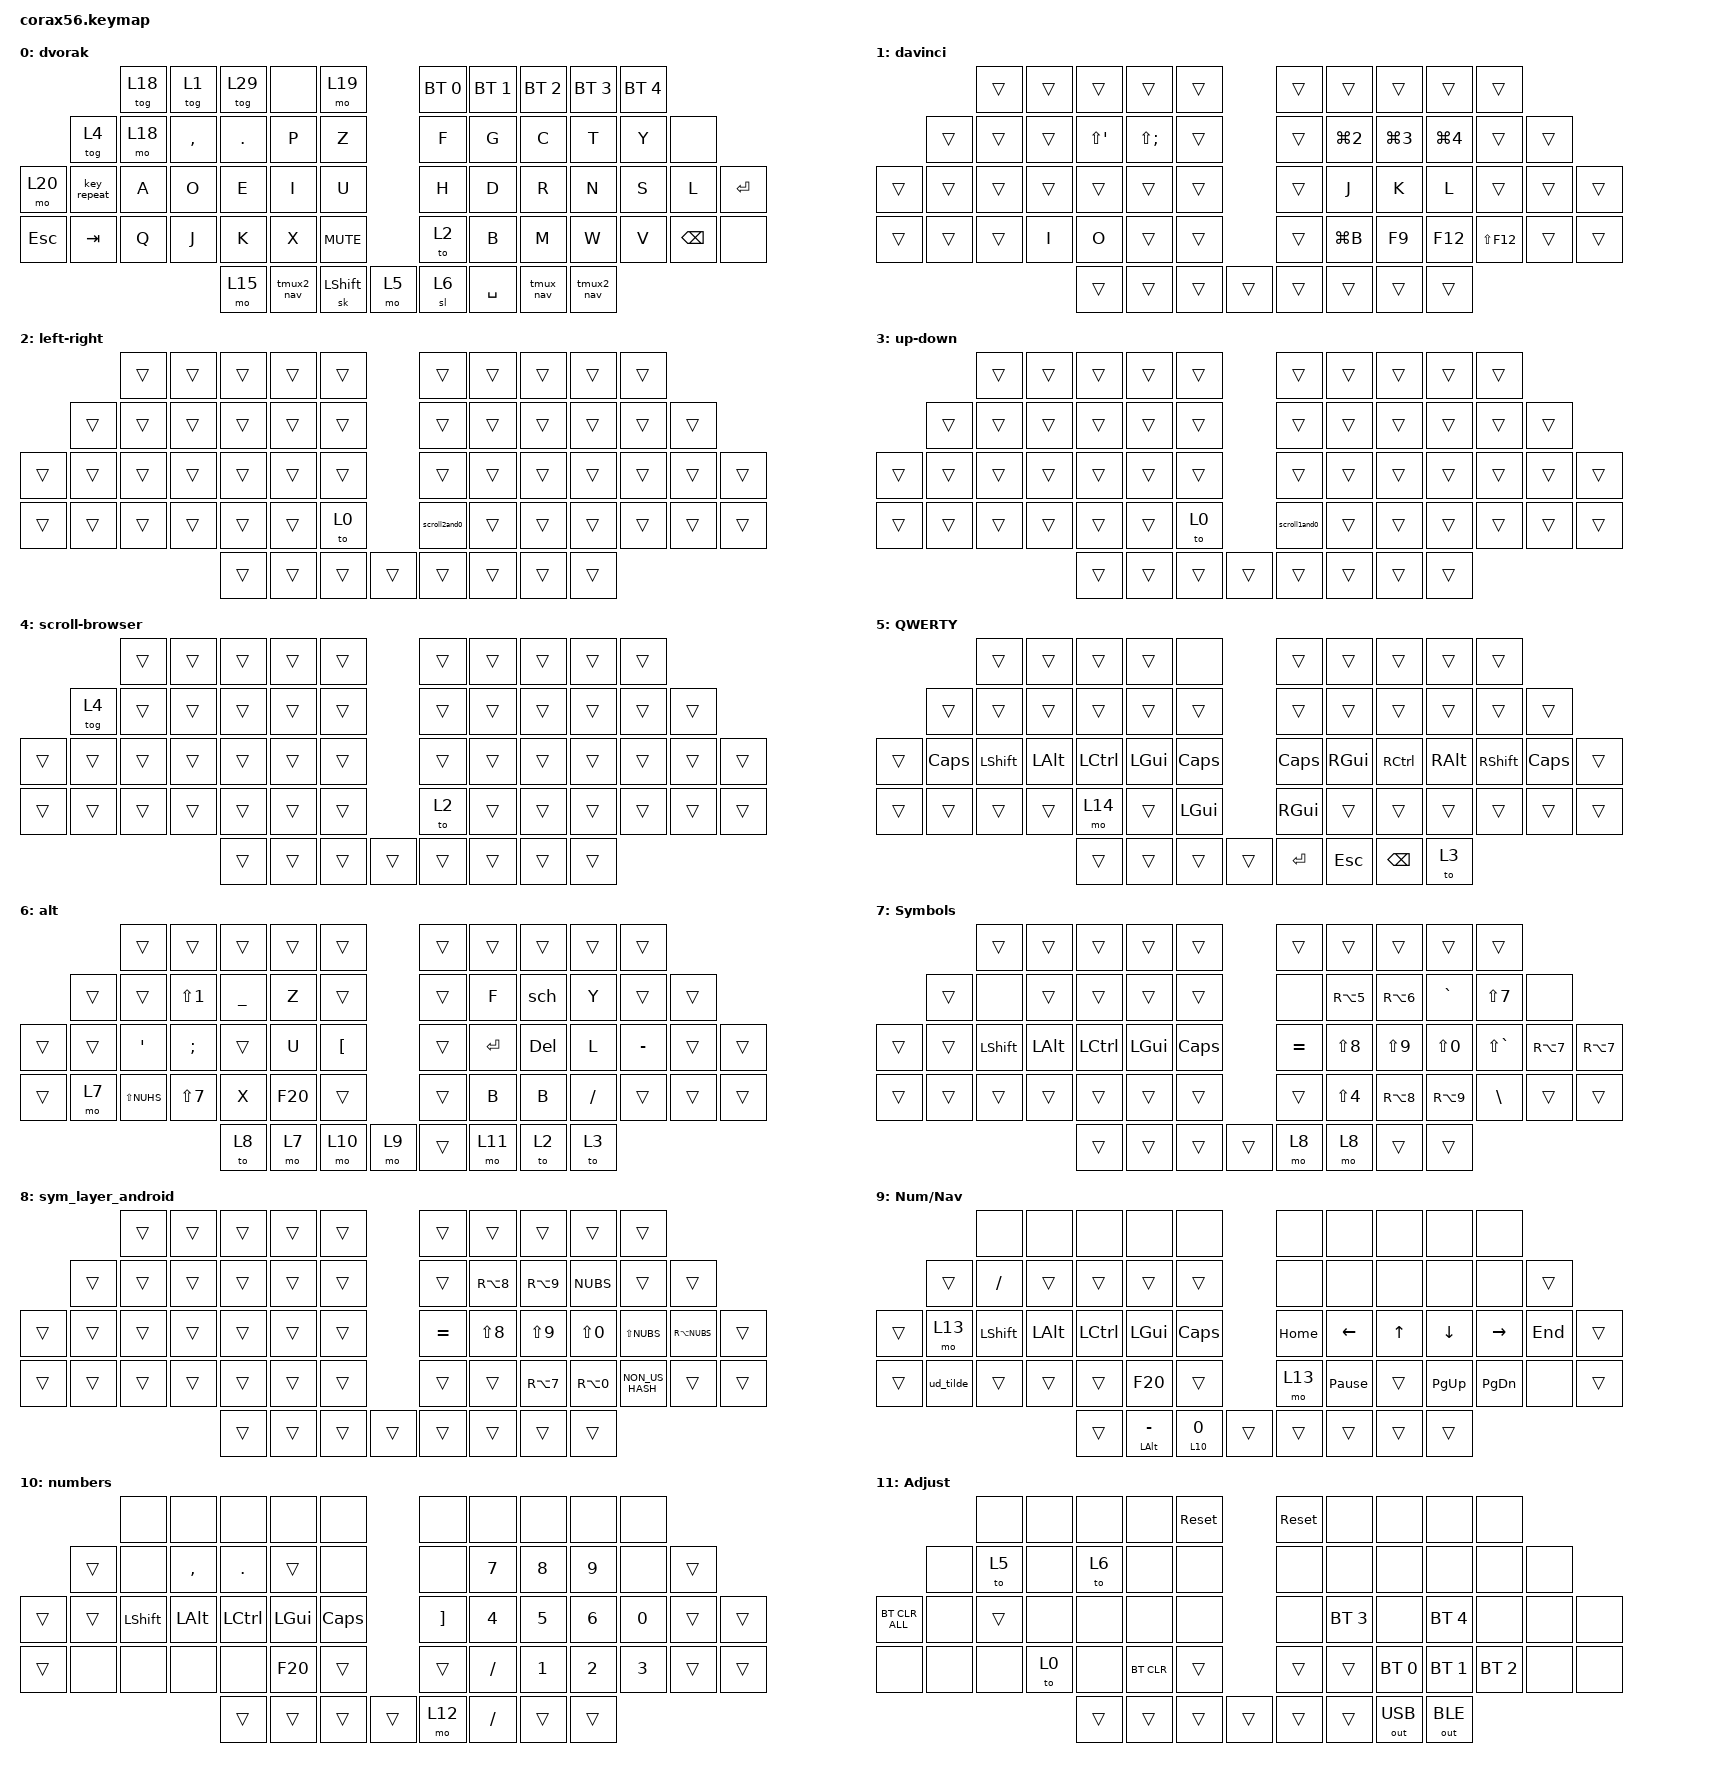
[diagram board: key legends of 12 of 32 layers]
#include <behaviors.dtsi>
#include <dt-bindings/zmk/bt.h>
#include <dt-bindings/zmk/keys.h>
#include <dt-bindings/zmk/outputs.h>

#define COLEMAK 0
#define QWERTY 1
#define WASD 2
#define SYM 3
#define NAV 4
#define DOUBLE 5
#define ADJUST 6

// additional caps word keys

&caps_word { continue-list = <UNDERSCORE MINUS LS(MINUS) UP DOWN LEFT RIGHT BSPC DEL>; };

/ {
    behaviors {
        lthp: layer_tap_hold_preferred {
            compatible = "zmk,behavior-hold-tap";
            #binding-cells = <2>;
            flavor = "hold-preferred";
            tapping-term-ms = <200>;
            bindings = <&mo>, <&kp>;
        };

        mthp: mod_tap_hold_preferred {
            compatible = "zmk,behavior-hold-tap";
            #binding-cells = <2>;
            flavor = "hold-preferred";
            tapping-term-ms = <200>;
            bindings = <&kp>, <&kp>;
        };

        shiftsticky: shiftsticky {
            compatible = "zmk,behavior-sticky-key";
            label = "SHIFTSTICKY";
            bindings = <&none>;
            #binding-cells = <1>;
            quick-release;
            release-after-ms = <1000>;
        };

        new_behavior: new_behavior {
            compatible = "zmk,behavior-hold-tap";
            label = "NEW_BEHAVIOR";
            bindings = <&none>, <&sk>;

            #binding-cells = <2>;
            tapping-term-ms = <10>;
        };

        scroll1and0: scroll1and0 {
            compatible = "zmk,behavior-tap-dance";
            label = "SCROLL1AND0";
            #binding-cells = <0>;
            bindings = <&to 2>, <&to 0>;
        };

        scroll2and0: scroll2and0 {
            compatible = "zmk,behavior-tap-dance";
            label = "SCROLL2AND0";
            #binding-cells = <0>;
            bindings = <&to 3>, <&to 0>;
        };


    };

    macros {
        tmux_nav: tmux_nav {
            compatible = "zmk,behavior-macro";
            #binding-cells = <0>;
            wait-ms = <10>;
            tap-ms = <10>;
            bindings
                = <&macro_press &mo 10>
                , <&macro_tap &kp LC(B)>
                , <&macro_pause_for_release>
                , <&macro_release &mo 10>
                ;
        };

        tmux2_nav: tmux2_nav {
            compatible = "zmk,behavior-macro";
            #binding-cells = <0>;
            wait-ms = <10>;
            tap-ms = <10>;
            bindings
                = <&macro_press &mo 10>
                , <&macro_tap &kp LC(B)>
                , <&macro_tap &kp LC(B)>
                , <&macro_pause_for_release>
                , <&macro_release &mo 10>
                ;
        };


        ud_grave: ud_grave {
            compatible = "zmk,behavior-macro";
            #binding-cells = <0>;
            wait-ms = <10>;
            tap-ms = <10>;
            bindings = <&kp GRAVE &kp SPACE>;
        };

        // undead ~

        ud_tilde: ud_tilde {
            compatible = "zmk,behavior-macro";
            #binding-cells = <0>;
            wait-ms = <10>;
            tap-ms = <10>;
            bindings = <&kp TILDE &kp SPACE>;
        };

        // undead ^

        ud_caret: ud_caret {
            compatible = "zmk,behavior-macro";
            #binding-cells = <0>;
            wait-ms = <10>;
            tap-ms = <10>;
            bindings = <&kp CARET &kp SPACE>;
        };

        // undead '

        ud_sqt: ud_sqt {
            compatible = "zmk,behavior-macro";
            #binding-cells = <0>;
            wait-ms = <10>;
            tap-ms = <10>;
            bindings = <&kp SQT &kp SPACE>;
        };

        // undead "

        ud_dqt: ud_dqt {
            compatible = "zmk,behavior-macro";
            #binding-cells = <0>;
            wait-ms = <10>;
            tap-ms = <10>;
            bindings = <&kp LS(SQT) &kp SPACE>;
        };

        // ascii arrow ->

        asc_arr: asc_arr {
            compatible = "zmk,behavior-macro";
            #binding-cells = <0>;
            wait-ms = <10>;
            tap-ms = <10>;
            bindings = <&kp MINUS &kp LS(DOT)>;
        };

        sch: sch {
            compatible = "zmk,behavior-macro";
            #binding-cells = <0>;
            bindings = <&kp S &kp C &kp H>;
            label = "SCH";
            wait-ms = <12>;
            tap-ms = <25>;
        };

        jonasgoogle: jonasgoogle {
            compatible = "zmk,behavior-macro";
            #binding-cells = <0>;
            bindings = <&kp J &kp O &kp N &kp A &kp S &kp DOT &kp R &kp U &kp L &kp I &kp K &kp LA(L) &kp G &kp O &kp O &kp G &kp L &kp E &kp M &kp A &kp I &kp L &kp DOT &kp C &kp O &kp M>;
            label = "JONASGOOGLE";
            wait-ms = <12>;
            tap-ms = <25>;
        };

        m7onas1ukas: m7onas1ukas {
            compatible = "zmk,behavior-macro";
            #binding-cells = <0>;
            bindings = <&kp N7 &kp O &kp N &kp A &kp S &kp N1 &kp U &kp K &kp A &kp S &kp LA(L) &kp G &kp O &kp O &kp G &kp L &kp E &kp M &kp A &kp I &kp L &kp DOT &kp C &kp O &kp M>;
            label = "M7ONAS1UKAS";
            wait-ms = <12>;
            tap-ms = <25>;
        };

        macro_192: macro_192 {
            compatible = "zmk,behavior-macro";
            #binding-cells = <0>;
            bindings = <&kp N1 &kp N9 &kp N2 &kp DOT &kp N1 &kp N6 &kp N8 &kp DOT &kp N1 &kp N7 &kp N8 &kp DOT>;
            label = "MACRO_192";
        };

    };

    combos {
        compatible = "zmk,combos";

        gm_capsword {
            bindings = <&caps_word>;

            // caps on G+M

            key-positions = <28 29>;
        };

        sticky_adjust {
            bindings = <&sl 11>;

            // sticky adjust layer on LALT+RALT

            key-positions = <51 56>;
        };

        wheel-default {
            bindings = <&to 0>;
            key-positions = <57 56>;
            layers = <6>;
        };
    };

    keymap {
        compatible = "zmk,keymap";

        dvorak {
            display-name = "dvorak";
            bindings = <
                     &tog 18  &tog 1     &tog 29     &none   &mo 19                          &bt BT_SEL 0  &bt BT_SEL 1  &bt BT_SEL 2  &bt BT_SEL 3  &bt BT_SEL 4
        &tog 4       &mo 18   &kp COMMA  &kp PERIOD  &kp P   &kp Z                           &kp F         &kp G         &kp C         &kp T         &kp Y          &none
&mo 20  &key_repeat  &kp A    &kp O      &kp E       &kp I   &kp U                           &kp H         &kp D         &kp R         &kp N         &kp S          &kp L  &kp ENTER
        &kp ESC      &kp TAB  &kp Q      &kp J       &kp K   &kp X      &kp K_MUTE    &to 2  &kp B         &kp M         &kp W         &kp V         &kp BACKSPACE  &none
                                         &mo 15      &tmux2_nav  &sk LSHFT  &mo 5         &sl 6  &kp SPACE     &tmux_nav        &tmux2_nav
            >;

            // sensor-bindings = <&as5600_scroll PG_DN PG_UP>;
        };

        davinci {
            bindings = <
                &trans  &trans  &trans        &trans        &trans                    &trans     &trans      &trans      &trans       &trans
        &trans  &trans  &trans  &kp LS(APOS)  &kp LS(SEMI)  &trans                    &trans     &kp LG(N2)  &kp LG(N3)  &kp LG(N4)   &trans  &trans
&trans  &trans  &trans  &trans  &trans        &trans        &trans                    &trans     &kp J       &kp K       &kp L        &trans  &trans  &trans
        &trans  &trans  &trans  &kp I         &kp O         &trans  &trans    &trans  &kp LG(B)  &kp F9      &kp F12     &kp LS(F12)  &trans  &trans
                                &trans        &trans        &trans  &trans    &trans  &trans     &trans      &trans
            >;
        };

        left-right {
            bindings = <
                &trans  &trans  &trans  &trans  &trans                          &trans  &trans  &trans  &trans  &trans
        &trans  &trans  &trans  &trans  &trans  &trans                          &trans  &trans  &trans  &trans  &trans  &trans
&trans  &trans  &trans  &trans  &trans  &trans  &trans                          &trans  &trans  &trans  &trans  &trans  &trans  &trans
        &trans  &trans  &trans  &trans  &trans  &trans  &to 0     &scroll2and0  &trans  &trans  &trans  &trans  &trans  &trans
                                &trans  &trans  &trans  &trans    &trans        &trans  &trans  &trans
            >;

            sensor-bindings =
                <&inc_dec_kp DOWN_ARROW UP_ARROW>,
                <&inc_dec_kp RA(RIGHT_ARROW) RA(LEFT_ARROW)>;
        };

        up-down {
            bindings = <
                &trans  &trans  &trans  &trans  &trans                          &trans  &trans  &trans  &trans  &trans
        &trans  &trans  &trans  &trans  &trans  &trans                          &trans  &trans  &trans  &trans  &trans  &trans
&trans  &trans  &trans  &trans  &trans  &trans  &trans                          &trans  &trans  &trans  &trans  &trans  &trans  &trans
        &trans  &trans  &trans  &trans  &trans  &trans  &to 0     &scroll1and0  &trans  &trans  &trans  &trans  &trans  &trans
                                &trans  &trans  &trans  &trans    &trans        &trans  &trans  &trans
            >;

            sensor-bindings = <&inc_dec_kp DOWN UP>, <&inc_dec_kp RIGHT LEFT>;
        };

        scroll-browser {
            bindings = <
                &trans  &trans  &trans  &trans  &trans                    &trans  &trans  &trans  &trans  &trans
        &tog 4  &trans  &trans  &trans  &trans  &trans                    &trans  &trans  &trans  &trans  &trans  &trans
&trans  &trans  &trans  &trans  &trans  &trans  &trans                    &trans  &trans  &trans  &trans  &trans  &trans  &trans
        &trans  &trans  &trans  &trans  &trans  &trans  &trans    &to 2   &trans  &trans  &trans  &trans  &trans  &trans
                                &trans  &trans  &trans  &trans    &trans  &trans  &trans  &trans
            >;

            sensor-bindings =
                <&inc_dec_kp RIGHT_ARROW LEFT_ARROW>,
                <&inc_dec_kp D E>;
        };

        home {
            display-name = "QWERTY";
            bindings = <
                      &trans     &trans    &trans            &trans    &none                                &trans        &trans         &trans             &trans    &trans
        &trans        &trans     &trans    &trans            &trans    &trans                               &trans        &trans         &trans             &trans    &trans     &trans
&trans  &kp CAPSLOCK  &kp LSHFT  &kp LALT  &kp LEFT_CONTROL  &kp LGUI  &kp CAPSLOCK                         &kp CAPSLOCK  &kp RGUI       &kp RIGHT_CONTROL  &kp RALT  &kp RSHFT  &kp CAPSLOCK  &trans
        &trans        &trans     &trans    &trans            &mo 14    &trans        &kp LGUI    &kp RGUI   &trans        &trans         &trans             &trans    &trans     &trans
                                           &trans            &trans    &trans        &trans      &kp ENTER  &kp ESC       &kp BACKSPACE  &to 3
            >;

            sensor-bindings =
                <&inc_dec_kp TAB LS(TAB)>,
                <&inc_dec_kp TAB RS(TAB)>;
        };

        alt {
            display-name = "alt";
            bindings = <
                &trans            &trans         &trans          &trans  &trans                              &trans  &trans     &trans     &trans  &trans
        &trans  &trans            &kp LS(N1)     &kp UNDERSCORE  &kp Z   &trans                              &trans  &kp F      &sch       &kp Y   &trans     &trans
&trans  &trans  &kp SINGLE_QUOTE  &kp SEMICOLON  &trans          &kp U   &kp LEFT_BRACKET                    &trans  &kp ENTER  &kp DEL    &kp L   &kp MINUS  &trans  &trans
        &trans  &mo 7             &kp LS(NUHS)   &kp LS(N7)      &kp X   &kp F20           &trans    &trans  &kp B   &kp B      &kp SLASH  &trans  &trans     &trans
                                                 &to 8           &mo 7   &mo 10            &mo 9     &trans  &mo 11  &to 2      &to 3
            >;

            sensor-bindings = <&inc_dec_kp J K>, <&inc_dec_kp W B>;
        };

        sym_layer {
            display-name = "Symbols";
            bindings = <
                &trans     &trans    &trans            &trans    &trans                          &trans      &trans      &trans      &trans         &trans
        &trans  &none      &trans    &trans            &trans    &trans                          &none       &kp RA(N5)  &kp RA(N6)  &kp GRAVE      &kp LS(N7)     &none
&trans  &trans  &kp LSHFT  &kp LALT  &kp LEFT_CONTROL  &kp LGUI  &kp CAPSLOCK                    &kp EQUAL   &kp LS(N8)  &kp LS(N9)  &kp LS(N0)     &kp LS(GRAVE)  &kp RA(N7)  &kp RA(N7)
        &trans  &trans     &trans    &trans            &trans    &trans        &trans    &trans  &kp LS(N4)  &kp RA(N8)  &kp RA(N9)  &kp BACKSLASH  &trans         &trans
                                     &trans            &trans    &trans        &trans    &mo 8   &mo 8       &trans      &trans
            >;

            sensor-bindings =
                <&inc_dec_kp C_BRI_DEC C_BRI_INC>,
                <&inc_dec_kp C_BRI_DN C_BRI_UP>;
        };

        sym_layer_android {
            bindings = <
                &trans  &trans  &trans  &trans  &trans                    &trans     &trans      &trans      &trans           &trans
        &trans  &trans  &trans  &trans  &trans  &trans                    &trans     &kp RA(N8)  &kp RA(N9)  &kp NUBS         &trans        &trans
&trans  &trans  &trans  &trans  &trans  &trans  &trans                    &kp EQUAL  &kp LS(N8)  &kp LS(N9)  &kp LS(N0)       &kp LS(NUBS)  &kp RA(NUBS)  &trans
        &trans  &trans  &trans  &trans  &trans  &trans  &trans    &trans  &trans     &kp RA(N7)  &kp RA(N0)  &kp NON_US_HASH  &trans        &trans
                                &trans  &trans  &trans  &trans    &trans  &trans     &trans      &trans
            >;
        };

        nav_layer {
            display-name = "Num/Nav";
            bindings = <
                &none      &none     &none             &none           &none                           &none            &none     &none      &none      &none
        &trans  &kp SLASH  &trans    &trans            &trans          &trans                          &none            &none     &none      &none      &none      &trans
&trans  &mo 13  &kp LSHFT  &kp LALT  &kp LEFT_CONTROL  &kp LGUI        &kp CAPSLOCK                    &kp HOME         &kp LEFT  &kp UP     &kp DOWN   &kp RIGHT  &kp END  &trans
        &trans  &ud_tilde  &trans    &trans            &trans          &kp F20       &trans    &mo 13  &kp PAUSE_BREAK  &trans    &kp PG_UP  &kp PG_DN  &none      &trans
                                     &trans            &mt LALT MINUS  &lt 10 N0     &trans    &trans  &trans           &trans    &trans
            >;

            sensor-bindings =
                <&inc_dec_kp DOWN_ARROW UP_ARROW>,
                <&inc_dec_kp RIGHT_ARROW LEFT_ARROW>;
        };

        number {
            display-name = "numbers";
            bindings = <
                &none      &none      &none      &none         &none                           &none              &none         &none         &none         &none
        &trans  &none      &kp COMMA  &kp DOT    &trans        &none                           &none              &kp N7        &kp N8        &kp N9        &none   &trans
&trans  &trans  &kp LSHFT  &kp LALT   &kp LCTRL  &kp LEFT_GUI  &kp CAPSLOCK                    &kp RIGHT_BRACKET  &kp N4        &kp N5        &kp NUMBER_6  &kp N0  &trans  &trans
        &trans  &none      &none      &none      &none         &kp F20       &trans    &trans  &kp SLASH          &kp NUMBER_1  &kp NUMBER_2  &kp NUMBER_3  &trans  &trans
                                      &trans     &trans        &trans        &trans    &mo 12  &kp SLASH          &trans        &trans
            >;

            sensor-bindings =
                <&inc_dec_kp C_VOL_DN C_VOL_UP>,
                <&inc_dec_kp C_NEXT C_PREV>;
        };

        bt {
            display-name = "Adjust";
            bindings = <
                       &none   &none  &none   &none   &sys_reset                    &sys_reset  &none         &none         &none         &none
                &none  &to 5   &none  &to 6   &none   &none                         &none       &none         &none         &none         &none  &none
&bt BT_CLR_ALL  &none  &trans  &none  &none   &none   &none                         &none       &bt BT_SEL 3  &none         &bt BT_SEL 4  &none  &none  &none
                &none  &none   &none  &to 0   &none   &bt BT_CLR  &trans    &trans  &trans      &bt BT_SEL 0  &bt BT_SEL 1  &bt BT_SEL 2  &none  &none
                                      &trans  &trans  &trans      &trans    &trans  &trans      &out OUT_USB  &out OUT_BLE
            >;

            sensor-bindings = <&inc_dec_kp C_VOL_DN C_VOL_UP &inc_dec_kp PG_DN PG_UP>;
        };

        functionNumber {
            bindings = <
                &none      &trans    &trans     &trans    &trans                    &trans   &trans  &trans  &trans  &trans
        &trans  &trans     &trans    &trans     &trans    &trans                    &trans   &kp F7  &kp F8  &kp F9  &trans  &trans
&trans  &trans  &kp LSHFT  &kp LALT  &kp LCTRL  &kp LGUI  &trans                    &kp F11  &kp F4  &kp F5  &kp F6  &trans  &trans  &trans
        &trans  &trans     &trans    &trans     &trans    &trans  &trans    &trans  &kp F12  &kp F1  &kp F2  &kp F3  &trans  &trans
                                     &trans     &trans    &trans  &trans    &trans  &kp F12  &trans  &trans
            >;
        };

        scroll-arrow-vert {
            bindings = <
                &trans  &trans  &trans  &trans  &trans                    &trans  &trans  &trans  &trans  &trans
        &trans  &trans  &trans  &trans  &trans  &trans                    &trans  &trans  &trans  &trans  &trans  &trans
&trans  &trans  &trans  &trans  &trans  &trans  &trans                    &trans  &trans  &trans  &trans  &trans  &trans  &trans
        &trans  &trans  &trans  &trans  &trans  &trans  &trans    &trans  &trans  &trans  &trans  &trans  &trans  &trans
                                &trans  &trans  &trans  &trans    &trans  &trans  &trans  &trans
            >;

            sensor-bindings =
                <&inc_dec_kp 0 0>,
                <&inc_dec_kp DOWN_ARROW UP_ARROW>;
        };

        media {
            bindings = <
                &trans  &trans  &trans  &trans  &trans                              &trans  &trans      &trans            &trans          &trans
        &trans  &trans  &trans  &trans  &trans  &trans                              &trans  &trans      &trans            &trans          &trans  &trans
&trans  &trans  &trans  &trans  &trans  &trans  &mo 17                              &trans  &kp C_PREV  &kp C_PLAY_PAUSE  &kp LA(C_NEXT)  &trans  &trans  &trans
        &trans  &trans  &trans  &trans  &trans  &trans  &mo 17    &kp C_PLAY_PAUSE  &trans  &trans      &trans            &trans          &trans  &trans
                                &trans  &trans  &trans  &trans    &trans            &trans  &trans      &trans
            >;

            sensor-bindings =
                <&inc_dec_kp C_VOL_DN C_VOL_UP>,
                <&inc_dec_kp C_BRI_DEC C_BRI_INC>;
        };

        undo-redo {
            bindings = <
                &trans  &trans  &trans  &trans  &trans                    &trans  &trans  &trans  &trans  &trans
        &trans  &trans  &trans  &trans  &trans  &trans                    &trans  &trans  &trans  &trans  &trans  &trans
&trans  &trans  &trans  &trans  &trans  &trans  &trans                    &trans  &trans  &trans  &trans  &trans  &trans  &trans
        &trans  &trans  &trans  &trans  &trans  &trans  &trans    &trans  &trans  &trans  &trans  &trans  &trans  &trans
                                &trans  &trans  &trans  &trans    &trans  &trans  &trans  &trans
            >;

            sensor-bindings =
                <&inc_dec_kp DEL BACKSPACE>,
                <&inc_dec_kp LS(LG(Y)) LG(Y)>;
        };

        right-wheel-delete {
            bindings = <
                &trans  &trans  &trans  &trans  &trans                    &trans  &trans  &trans  &trans  &trans
        &trans  &trans  &trans  &trans  &trans  &trans                    &trans  &trans  &trans  &trans  &trans  &trans
&trans  &trans  &trans  &trans  &trans  &trans  &trans                    &trans  &trans  &trans  &trans  &trans  &trans  &trans
        &trans  &trans  &trans  &trans  &trans  &trans  &trans    &trans  &trans  &trans  &trans  &trans  &trans  &trans
                                &trans  &trans  &trans  &trans    &trans  &trans  &trans  &trans
            >;

            sensor-bindings = <&inc_dec_kp 0 0>, <&inc_dec_kp DEL BACKSPACE>;
        };

        Brightness {
            bindings = <
                &trans  &trans  &trans  &trans  &trans                    &trans  &trans  &trans  &trans  &trans
        &trans  &trans  &trans  &trans  &trans  &trans                    &trans  &trans  &trans  &trans  &trans  &trans
&trans  &trans  &trans  &trans  &trans  &trans  &trans                    &trans  &trans  &trans  &trans  &trans  &trans  &trans
        &trans  &trans  &trans  &trans  &trans  &trans  &trans    &trans  &trans  &trans  &trans  &trans  &trans  &trans
                                &trans  &trans  &trans  &trans    &trans  &trans  &trans  &trans
            >;

            sensor-bindings = <&inc_dec_kp C_BRI_DN C_BRI_UP>;
        };

        vscode-wheel {
            bindings = <
                &trans  &trans  &trans  &trans  &trans                    &trans  &trans  &trans  &trans  &trans
        &trans  &trans  &trans  &trans  &trans  &trans                    &trans  &trans  &trans  &trans  &trans  &trans
&trans  &trans  &trans  &trans  &trans  &trans  &trans                    &trans  &trans  &trans  &trans  &trans  &trans  &trans
        &trans  &trans  &trans  &trans  &trans  &trans  &trans    &to 2   &trans  &trans  &trans  &trans  &trans  &trans
                                &trans  &trans  &trans  &trans    &trans  &trans  &trans  &trans
            >;

            sensor-bindings =
                <&inc_dec_kp LA(LG(LC(PAGE_DOWN))) LA(LC(LG(PAGE_UP)))>,
                <&inc_dec_kp LA(F5) LA(LS(F5))>;
        };

        mail {
            bindings = <
                &trans  &trans  &trans  &trans  &trans                    &jonasgoogle  &m7onas1ukas  &trans  &trans  &macro_192
        &trans  &trans  &trans  &trans  &trans  &trans                    &trans        &trans        &trans  &trans  &trans      &trans
&trans  &trans  &trans  &trans  &trans  &trans  &trans                    &trans        &trans        &trans  &trans  &trans      &trans  &trans
        &trans  &trans  &trans  &trans  &trans  &trans  &trans    &trans  &trans        &trans        &trans  &trans  &trans      &trans
                                &trans  &trans  &trans  &trans    &trans  &trans        &trans        &trans
            >;
        };

        scrolling {
            bindings = <
                &trans  &trans  &trans  &trans  &trans                    &trans  &trans  &trans  &trans  &trans
        &trans  &trans  &trans  &trans  &trans  &trans                    &trans  &trans  &to 25  &trans  &to 27  &trans
&trans  &trans  &trans  &trans  &trans  &trans  &trans                    &trans  &to 4   &to 18  &to 24  &trans  &trans  &trans
        &trans  &trans  &trans  &trans  &trans  &trans  &trans    &trans  &to 22  &to 23  &to 26  &to 21  &trans  &trans
                                &trans  &trans  &trans  &trans    &trans  &trans  &trans  &trans
            >;
        };

        scrolling-find {
            bindings = <
                &trans  &trans  &trans  &trans  &trans                    &trans  &trans  &trans  &trans  &trans
        &trans  &trans  &trans  &trans  &trans  &trans                    &trans  &trans  &trans  &trans  &trans  &trans
&trans  &trans  &trans  &trans  &trans  &trans  &trans                    &trans  &trans  &trans  &trans  &trans  &trans  &trans
        &trans  &trans  &trans  &trans  &trans  &trans  &trans    &to 2   &trans  &trans  &trans  &trans  &trans  &trans
                                &trans  &trans  &trans  &trans    &trans  &trans  &trans  &trans
            >;

            sensor-bindings = <&inc_dec_kp F4 LS(F4)>, <&inc_dec_kp F3 LS(F3)>;
        };

        scroll-vim-navigation {
            bindings = <
                &trans  &trans  &trans  &trans  &trans                    &trans  &trans  &trans  &trans  &trans
        &trans  &trans  &trans  &trans  &trans  &trans                    &trans  &trans  &trans  &trans  &trans  &trans
&trans  &trans  &trans  &trans  &trans  &trans  &trans                    &trans  &trans  &trans  &trans  &trans  &trans  &trans
        &trans  &trans  &trans  &trans  &trans  &trans  &trans    &to 2   &trans  &trans  &trans  &trans  &trans  &trans
                                &trans  &trans  &trans  &trans    &trans  &trans  &trans  &trans
            >;

            sensor-bindings = <&inc_dec_kp J K>, <&inc_dec_kp W B>;
        };

        scroll-vim-block {
            bindings = <
                &trans  &trans  &trans  &trans  &trans                    &trans  &trans  &trans  &trans  &trans
        &trans  &trans  &trans  &trans  &trans  &trans                    &trans  &trans  &trans  &trans  &trans  &trans
&trans  &trans  &trans  &trans  &trans  &trans  &trans                    &trans  &trans  &trans  &trans  &trans  &trans  &trans
        &trans  &trans  &trans  &trans  &trans  &trans  &trans    &to 2   &trans  &trans  &trans  &trans  &trans  &trans
                                &trans  &trans  &trans  &trans    &trans  &trans  &trans  &trans
            >;

            sensor-bindings =
                <&inc_dec_kp N LS(N)>,
                <&inc_dec_kp LA(N9) LA(N8)>;
        };

        scroll-vsc-bracket {
            bindings = <
                &trans  &trans  &trans  &trans  &trans                    &trans  &trans  &trans  &trans  &trans
        &trans  &trans  &trans  &trans  &trans  &trans                    &trans  &trans  &trans  &trans  &trans  &trans
&trans  &trans  &trans  &trans  &trans  &trans  &trans                    &trans  &trans  &trans  &trans  &trans  &trans  &trans
        &trans  &trans  &trans  &trans  &trans  &trans  &trans    &to 2   &trans  &trans  &trans  &trans  &trans  &trans
                                &trans  &trans  &trans  &trans    &trans  &trans  &trans  &trans
            >;

            sensor-bindings =
                <&inc_dec_kp LA(LC(LG(DOWN))) LA(LC(LG(UP)))>,
                <&inc_dec_kp LA(LC(LG(RIGHT))) LA(LC(LG(LEFT)))>;
        };

        wheel-vscode-problems {
            bindings = <
                &trans  &trans  &trans  &trans  &trans                    &trans  &trans  &trans  &trans  &trans
        &trans  &trans  &trans  &trans  &trans  &trans                    &trans  &trans  &trans  &trans  &trans  &trans
&trans  &trans  &trans  &trans  &trans  &trans  &trans                    &trans  &trans  &trans  &trans  &trans  &trans  &trans
        &trans  &trans  &trans  &trans  &trans  &trans  &trans    &to 2   &trans  &trans  &trans  &trans  &trans  &trans
                                &trans  &trans  &trans  &trans    &trans  &trans  &trans  &trans
            >;

            sensor-bindings =
                <&inc_dec_kp LA(F5) LA(LS(F5))>,
                <&inc_dec_kp LA(F8) LA(LS(F8))>;
        };

        wheel-vscode-editor-size {
            bindings = <
                &trans  &trans  &trans  &trans  &trans                       &trans  &trans  &trans  &trans  &trans
        &trans  &trans  &trans  &trans  &trans  &trans                       &trans  &trans  &trans  &trans  &trans  &trans
&trans  &trans  &trans  &trans  &trans  &trans  &trans                       &trans  &trans  &trans  &trans  &trans  &trans  &trans
        &trans  &trans  &trans  &trans  &trans  &trans  &kp LG(J)    &to 2   &trans  &trans  &trans  &trans  &trans  &trans
                                &trans  &trans  &trans  &trans       &trans  &trans  &trans  &trans
            >;

            sensor-bindings =
                <&inc_dec_kp LS(LA(LC(LG(DOWN_ARROW)))) LS(LA(LC(LG(UP_ARROW))))>,
                <&inc_dec_kp LA(LS(LC(LG(RIGHT)))) LS(LA(LC(LG(LEFT))))>;
        };

        wheel-vscode-goback {
            bindings = <
                &trans  &trans  &trans  &trans  &trans                    &trans  &trans  &trans  &trans  &trans
        &trans  &trans  &trans  &trans  &trans  &trans                    &trans  &trans  &trans  &trans  &trans  &trans
&trans  &trans  &trans  &trans  &trans  &trans  &trans                    &trans  &trans  &trans  &trans  &trans  &trans  &trans
        &trans  &trans  &trans  &trans  &trans  &trans  &trans    &to 2   &trans  &trans  &trans  &trans  &trans  &trans
                                &trans  &trans  &trans  &trans    &trans  &trans  &trans  &trans
            >;

            sensor-bindings =
                <&inc_dec_kp LA(LC(SLASH)) LA(LC(LS(SLASH)))>,
                <&inc_dec_kp LS(LC(SLASH)) LC(SLASH)>;
        };

        tmux {
            bindings = <
                &trans  &to 0   &trans  &trans  &trans                    &trans  &trans     &trans           &trans  &trans
        &trans  &trans  &trans  &trans  &trans  &trans                    &trans  &trans     &trans           &trans  &trans  &kp C
&trans  &trans  &trans  &trans  &trans  &trans  &trans                    &trans  &trans     &trans           &trans  &trans  &trans  &trans
        &trans  &trans  &trans  &trans  &trans  &trans  &trans    &trans  &trans  &trans     &trans           &trans  &trans  &trans
                                &trans  &trans  &mo 30  &trans    &trans  &trans  &kp RC(B)  &kp RC(B)
            >;
        };

        left_wasd {
            bindings = <
                &trans  &trans  &trans  &trans  &trans                    &trans    &trans    &trans     &trans     &trans
        &trans  &trans  &kp Q   &kp W   &kp E   &trans                    &trans    &trans    &trans     &trans     &trans     &trans
&trans  &trans  &trans  &kp A   &kp S   &kp D   &trans                    &kp HOME  &kp LEFT  &kp UP     &kp DOWN   &kp RIGHT  &kp END  &trans
        &trans  &trans  &trans  &trans  &trans  &trans  &trans    &trans  &trans    &trans    &kp PG_UP  &kp PG_DN  &trans     &trans
                                &trans  &trans  &trans  &trans    &trans  &trans    &trans    &trans
            >;
        };

        tmux_number {
            bindings = <
                &trans  &trans  &trans  &trans  &trans                    &trans  &trans  &trans  &trans  &trans
        &trans  &trans  &trans  &trans  &trans  &trans                    &trans  &kp N7  &kp N8  &kp N9  &trans  &trans
&trans  &trans  &trans  &trans  &trans  &trans  &trans                    &trans  &kp N4  &kp N5  &kp N6  &kp N0  &trans  &trans
        &trans  &trans  &trans  &trans  &trans  &trans  &trans    &trans  &trans  &kp N1  &kp N2  &kp N3  &trans  &trans
                                &trans  &trans  &trans  &trans    &trans  &trans  &trans  &trans
            >;
        };

        tmux_2nd_layer {
            bindings = <
                &trans  &trans  &trans  &trans  &trans                    &trans  &trans  &trans  &trans  &trans
        &trans  &trans  &trans  &trans  &trans  &trans                    &trans  &trans  &trans  &trans  &trans  &trans
&trans  &trans  &trans  &trans  &trans  &trans  &trans                    &trans  &trans  &trans  &trans  &trans  &trans  &trans
        &trans  &trans  &trans  &trans  &trans  &trans  &trans    &trans  &trans  &trans  &trans  &trans  &trans  &trans
                                &trans  &trans  &trans  &trans    &trans  &trans  &trans  &trans
            >;
        };
    };
};
